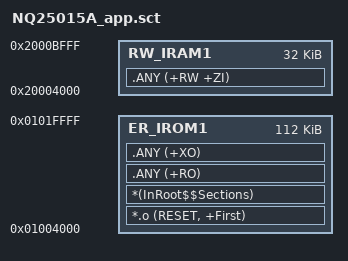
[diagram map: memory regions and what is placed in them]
; *************************************************************
; *** Custom Scatter File for NQ25015A APP1 (OTA Dual-Bank)  ***
; *************************************************************
;
; Flash layout (N32WB03X, 256KB total):
;   0x01000000  Masterboot     8KB   (separate project, not part of this build)
;   0x01002000  Bootsetting    4KB   (accessed via pointer cast, not placed here)
;   0x01003000  AppData        4KB
;   0x01004000  APP1          112KB  <-- this application
;   0x01020000  APP2          112KB  (OTA slot)
;   0x0103C000  ImageUpdate    16KB  (DFU buffer)
;
; Note: Bootsetting is accessed via macro (pointer cast to 0x01002000),
;       not via a linker-placed section, so no UNINIT region needed here.

; APP1: starts at 0x01004000, max 112KB (ends before APP2 at 0x01020000)
LR_IROM1 0x01004000 0x0001C000  {
  ER_IROM1 0x01004000 0x0001C000  {
    *.o (RESET, +First)
    *(InRoot$$Sections)
    .ANY (+RO)
    .ANY (+XO)
  }
  RW_IRAM1 0x20004000 0x00008000  {  ; RW data (32KB, BLE stack uses lower RAM)
    .ANY (+RW +ZI)
  }
}
